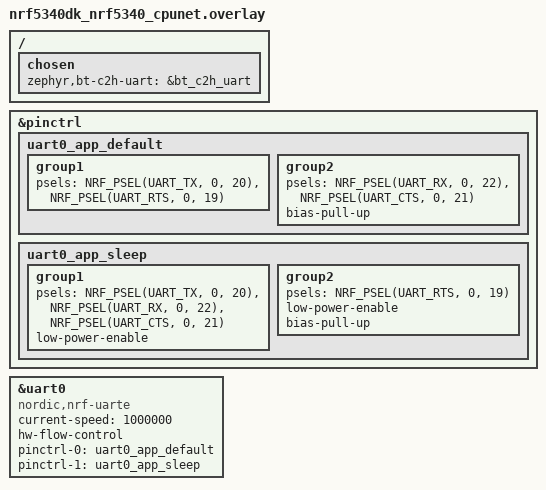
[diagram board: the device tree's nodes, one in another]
/*
 * Copyright (c) 2026 Nordic Semiconductor ASA
 *
 * SPDX-License-Identifier: LicenseRef-Nordic-5-Clause
 */

/* Use the app core UART pins when running from the network core. */
&pinctrl {
	uart0_app_default: uart0_app_default {
		group1 {
			psels = <NRF_PSEL(UART_TX, 0, 20)>,
				<NRF_PSEL(UART_RTS, 0, 19)>;
		};
		group2 {
			psels = <NRF_PSEL(UART_RX, 0, 22)>,
				<NRF_PSEL(UART_CTS, 0, 21)>;
			bias-pull-up;
		};
	};

	/* NCSDK-36190: keep RTS pulled up while the UART sleeps between packets. */
	uart0_app_sleep: uart0_app_sleep {
		group1 {
			psels = <NRF_PSEL(UART_TX, 0, 20)>,
				<NRF_PSEL(UART_RX, 0, 22)>,
				<NRF_PSEL(UART_CTS, 0, 21)>;
			low-power-enable;
		};
		group2 {
			psels = <NRF_PSEL(UART_RTS, 0, 19)>;
			low-power-enable;
			bias-pull-up;
		};
	};
};

bt_c2h_uart: &uart0 {
	compatible = "nordic,nrf-uarte";
	current-speed = <1000000>;
	status = "okay";
	hw-flow-control;
	pinctrl-0 = <&uart0_app_default>;
	pinctrl-1 = <&uart0_app_sleep>;
	pinctrl-names = "default", "sleep";
};

/ {
	chosen {
		zephyr,bt-c2h-uart = &bt_c2h_uart;
		/delete-property/ zephyr,console;
		/delete-property/ zephyr,shell-uart;
		/delete-property/ zephyr,uart-mcumgr;
		/delete-property/ zephyr,bt-mon-uart;
	};
};

